# STM32C071 register map
File version: 1.3
CPU: CM0+ r0p0, little endian, MPU, no FPU, 2 interrupt priority bits
Registers are 32-bit, read-write, reset 0x0 unless marked. A register's access mark holds for its fields unless they carry their own. Offsets are from the block's base; [hi:lo] are bit positions.

## RCC — RCC address block description
Base 0x40021000
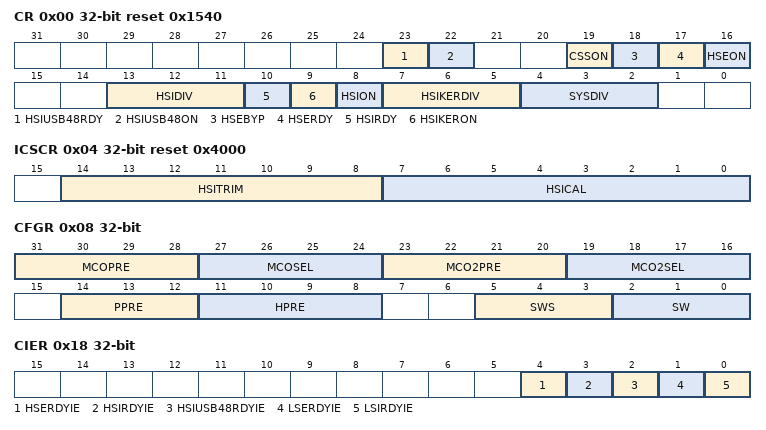
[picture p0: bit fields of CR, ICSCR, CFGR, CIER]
0x00 CR reset 0x1540 — RCC clock control register
  [23] HSIUSB48RDY — HSIUSB48 clock ready flag Set by hardware when the HSIUSB48 oscillator is enabled through HSIUSB48ON and ready to use (stable). Note: Only applicable on STM32C071xx, reserved on other devices.
  [22] HSIUSB48ON — HSIUSB48 clock enable Set and cleared by software and hardware, with hardware taking priority. Kept low by hardware as long as the device is in a low-power mode. Kept high by hardware as long as the system is clocked from HSIUSB48. Note: Only applicable on STM32C071xx, reserved on other devices.
  [19] CSSON — Clock security system enable Set by software to enable the clock security system. When the bit is set, the clock detector is enabled by hardware when the HSE oscillator is ready, and disabled by hardware if a HSE clock failure is detected. The bit is cleared by hardware upon reset.
  [18] HSEBYP — HSE crystal oscillator bypass Set and cleared by software. When the bit is set, the internal HSE oscillator is bypassed for use of an external clock. The external clock must then be enabled with the HSEON bit set. Write access to the bit is only effective when the HSE oscillator is disabled.
  [17] HSERDY ro — HSE clock ready flag Set by hardware to indicate that the HSE oscillator is stable and ready for use. Note: Upon clearing HSEON, HSERDY goes low after six HSE clock cycles.
  [16] HSEON — HSE clock enable Set and cleared by software. Cleared by hardware to stop the HSE oscillator when entering Stop, or Standby, or Shutdown mode. This bit cannot be cleared if the HSE oscillator is used directly or indirectly as the system clock.
  [13:11] HSIDIV — HSI48 clock division factor This bitfield controlled by software sets the division factor of the HSI48 clock divider to produce HSISYS clock:
  [10] HSIRDY ro — HSI48 clock ready flag Set by hardware when the HSI48 oscillator is enabled through HSION and ready to use (stable). Note: Upon clearing HSION, HSIRDY goes low after six HSI48 clock cycles.
  [9] HSIKERON — HSI48 always-enable for peripheral kernels. Set and cleared by software. Setting the bit activates the HSI48 oscillator in Run and Stop modes, regardless of the HSION bit state. The HSI48 clock can only feed USART1, USART2, and I2C1 peripherals configured with HSI48 as kernel clock. Note: Keeping the HSI48 active in Stop mode allows speeding up the serial interface communication as the HSI48 clock is ready immediately upon exiting Stop mode.
  [8] HSION — HSI48 clock enable Set and cleared by software and hardware, with hardware taking priority. Kept low by hardware as long as the device is in a low-power mode. Kept high by hardware as long as the system is clocked with a clock derived from HSI48. This includes the exit from low-power modes and the system clock fall-back to HSI48 upon failing HSE oscillator clock selected as system clock source.
  [7:5] HSIKERDIV — HSI48 kernel clock division factor This bitfield controlled by software sets the division factor of the kernel clock divider to produce HSIKER clock:
  [4:2] SYSDIV — Clock division factor for system clock Set and cleared by software. SYSCLK is result of the division by: Note: This bitfield is only available on STM32C071xx.
0x04 ICSCR reset 0x4000 (reset mask 0xFFFFFF00) — RCC internal clock source calibration register
  [14:8] HSITRIM — HSI48 clock trimming The value of this bitfield contributes to the HSICAL[7:0] bitfield value. It allows HSI48 clock frequency user trimming. The HSI48 frequency accuracy as stated in the device datasheet applies when this bitfield is left at its reset value.
  [7:0] HSICAL ro — HSI48 clock calibration This bitfield directly acts on the HSI48 clock frequency. Its value is a sum of an internal factory-programmed number and the value of the HSITRIM[6:0] bitfield. In the factory, the internal number is set to calibrate the HSI48 clock frequency to 48 MHz (with HSITRIM[6:0] left at its reset value). Refer to the device datasheet for HSI48 calibration accuracy and for the frequency trimming granularity. Note: The trimming effect presents discontinuities at HSICAL[7:0] multiples of 64.
0x08 CFGR — RCC clock configuration register
  [31:28] MCOPRE — Microcontroller clock output prescaler This bitfield is controlled by software. It sets the division factor of the clock sent to the MCO output as follows: ... Other: Reserved It is highly recommended to set this field before the MCO output is enabled. Note: Values above 0111 are only significant for STM32C071xx. On STM32C011xx and STM32C031xx devices, MCOPRE[3] is reserved.
  [27:24] MCOSEL — Microcontroller clock output clock selector This bitfield is controlled by software. It sets the clock selector for MCO output as follows: Other: reserved, must not be used Note: This clock output may have some truncated cycles at startup or during MCO clock source switching. On STM32C011xx and STM32C031xx, MCOSEL[3] is reserved.
  [23:20] MCO2PRE — Microcontroller clock output 2 prescaler This bitfield is controlled by software. It sets the division factor of the clock sent to the MCO2 output as follows: ... Other: Reserved It is highly recommended to set this field before the MCO2 output is enabled. Note: Values above 0111 are only significant for STM32C071xx. On STM32C011xx and STM32C031xx devices, MCOPRE[3] is reserved.
  [19:16] MCO2SEL — Microcontroller clock output 2 clock selector This bitfield is controlled by software. It sets the clock selector for MCO2 output as follows: Other: reserved, must not be used Note: This clock output may have some truncated cycles at startup or during MCO2 clock source switching. On STM32C011xx and STM32C031xx, MCOSEL[3] is reserved.
  [14:12] PPRE — APB prescaler This bitfield is controlled by software. To produce PCLK clock, it sets the division factor of HCLK clock as follows: 0xx: 1
  [11:8] HPRE — AHB prescaler This bitfield is controlled by software. To produce HCLK clock, it sets the division factor of SYSCLK clock as follows: 0xxx: 1
  [5:3] SWS ro — System clock switch status This bitfield is controlled by hardware to indicate the clock source used as system clock: Others: Reserved
  [2:0] SW — System clock switch This bitfield is controlled by software and hardware. The bitfield selects the clock for SYSCLK as follows: Others: Reserved The setting is forced by hardware to 000 (HSISYS selected) when the MCU exits Stop, or Standby, or Shutdown mode, or when the setting is 001 (HSE selected) and HSE oscillator failure is detected.
0x14 CRRCR ro (reset mask 0xFFFFFE00) — RCC clock recovery RC register
  [8:0] HSIUSB48CAL — HSIUSB48 clock calibration These bits are initialized at startup with the factory-programmed HSIUSB48 calibration trim value.
0x18 CIER — RCC clock interrupt enable register
  [4] HSERDYIE — HSE ready interrupt enable Set and cleared by software to enable/disable interrupt caused by the HSE oscillator stabilization:
  [3] HSIRDYIE — HSI48 ready interrupt enable Set and cleared by software to enable/disable interrupt caused by the HSI48 oscillator stabilization:
  [2] HSIUSB48RDYIE — HSIUSB48 ready interrupt enable Set and cleared by software to enable/disable interrupt caused by the HSIUSB48 oscillator stabilization: Note: Only applicable on STM32C071xx, reserved on other devices.
  [1] LSERDYIE — LSE ready interrupt enable Set and cleared by software to enable/disable interrupt caused by the LSE oscillator stabilization:
  [0] LSIRDYIE — LSI ready interrupt enable Set and cleared by software to enable/disable interrupt caused by the LSI oscillator stabilization:
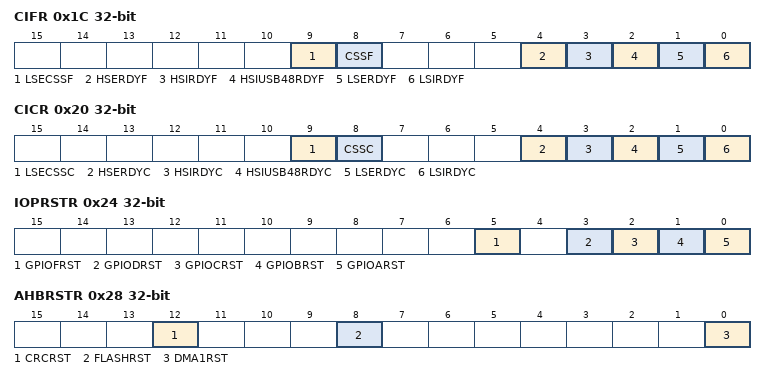
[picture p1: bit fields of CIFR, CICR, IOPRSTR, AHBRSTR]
0x1C CIFR ro — RCC clock interrupt flag register
  [9] LSECSSF — LSE clock security system interrupt flag This flag indicates a pending interrupt upon LSE clock failure. Set by hardware when a failure is detected in the LSE oscillator. Cleared by software by setting the LSECSSC bit.
  [8] CSSF — HSE clock security system interrupt flag This flag indicates a pending interrupt upon HSE clock failure. Set by hardware when a failure is detected in the HSE oscillator. Cleared by software setting the CSSC bit.
  [4] HSERDYF — HSE ready interrupt flag This flag indicates a pending interrupt upon HSE clock getting ready. Set by hardware when the HSE clock becomes stable and HSERDYIE is set. Cleared by software setting the HSERDYC bit.
  [3] HSIRDYF — HSI48 ready interrupt flag This flag indicates a pending interrupt upon HSI48 clock getting ready. Set by hardware when the HSI48 clock becomes stable and HSIRDYIE is set in response to setting the HSION (refer to RCC clock control register (RCC_CR)). When HSION is not set but the HSI48 oscillator is enabled by the peripheral through a clock request, this bit is not set and no interrupt is generated. Cleared by software setting the HSIRDYC bit.
  [2] HSIUSB48RDYF — HSIUSB48 ready interrupt flag Set by hardware when the HSIUSB48 clock becomes stable and HSIUSB48RDYIE is set as a response to setting HSIUSB48ON (refer to RCC clock control register (RCC_CR)). When HSIUSB48ON is not set but the HSIUSB48 oscillator is enabled by the peripheral through a clock request, this bit is not set and no interrupt is generated. Cleared by software setting the HSIUSB48RDYC bit. Note: Only applicable on STM32C071xx, reserved on other devices.
  [1] LSERDYF — LSE ready interrupt flag This flag indicates a pending interrupt upon LSE clock getting ready. Set by hardware when the LSE clock becomes stable and LSERDYDIE is set. Cleared by software setting the LSERDYC bit.
  [0] LSIRDYF — LSI ready interrupt flag This flag indicates a pending interrupt upon LSE clock getting ready. Set by hardware when the LSI clock becomes stable and LSIRDYDIE is set. Cleared by software setting the LSIRDYC bit.
0x20 CICR wo — RCC clock interrupt clear register
  [9] LSECSSC — LSE Clock security system interrupt clear This bit is set by software to clear the LSECSSF flag.
  [8] CSSC — Clock security system interrupt clear This bit is set by software to clear the HSECSSF flag.
  [4] HSERDYC — HSE ready interrupt clear This bit is set by software to clear the HSERDYF flag.
  [3] HSIRDYC — HSI48 ready interrupt clear This bit is set software to clear the HSIRDYF flag.
  [2] HSIUSB48RDYC — HSIUSB48 ready interrupt clear This bit is set software to clear the HSIUSB48RDYF flag. Note: Only applicable on STM32C071xx, reserved on other devices.
  [1] LSERDYC — LSE ready interrupt clear This bit is set by software to clear the LSERDYF flag.
  [0] LSIRDYC — LSI ready interrupt clear This bit is set by software to clear the LSIRDYF flag.
0x24 IOPRSTR — RCC I/O port reset register
  [5] GPIOFRST — I/O port F reset This bit is set and cleared by software.
  [3] GPIODRST — I/O port D reset This bit is set and cleared by software.
  [2] GPIOCRST — I/O port C reset This bit is set and cleared by software.
  [1] GPIOBRST — I/O port B reset This bit is set and cleared by software.
  [0] GPIOARST — I/O port A reset This bit is set and cleared by software.
0x28 AHBRSTR — RCC AHB peripheral reset register
  [12] CRCRST — CRC reset Set and cleared by software.
  [8] FLASHRST — Flash memory interface reset Set and cleared by software. This bit can only be set when the Flash memory is in power down mode.
  [0] DMA1RST — DMA1 and DMAMUX reset Set and cleared by software.
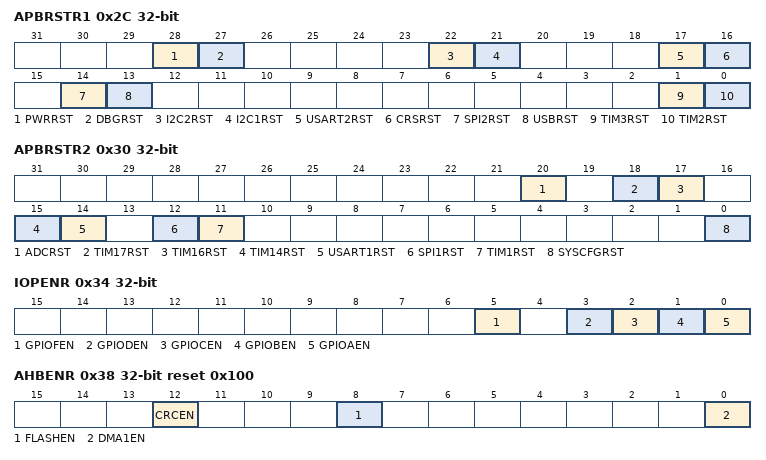
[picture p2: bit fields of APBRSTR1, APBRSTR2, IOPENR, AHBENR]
0x2C APBRSTR1 — RCC APB peripheral reset register 1
  [28] PWRRST — Power interface reset Set and cleared by software.
  [27] DBGRST — Debug support reset Set and cleared by software.
  [22] I2C2RST — I2C2 reset Set and cleared by software. Note: Only applicable on STM32C071xx, reserved on other devices.
  [21] I2C1RST — I2C1 reset Set and cleared by software.
  [17] USART2RST — USART2 reset Set and cleared by software.
  [16] CRSRST — CRS reset Set and cleared by software. Note: Only applicable on STM32C071xx, reserved on other devices.
  [14] SPI2RST — SPI2 reset Set and cleared by software. Note: Only applicable on STM32C071xx, reserved on other devices.
  [13] USBRST — USB reset Set and cleared by software. Note: Only applicable on STM32C071xx, reserved on other devices.
  [1] TIM3RST — TIM3 timer reset Set and cleared by software.
  [0] TIM2RST — TIM2 timer reset Set and cleared by software. Note: Only applicable on STM32C071xx, reserved on other devices.
0x30 APBRSTR2 — RCC APB peripheral reset register 2
  [20] ADCRST — ADC reset Set and cleared by software.
  [18] TIM17RST — TIM16 timer reset Set and cleared by software.
  [17] TIM16RST — TIM16 timer reset Set and cleared by software.
  [15] TIM14RST — TIM14 timer reset Set and cleared by software.
  [14] USART1RST — USART1 reset Set and cleared by software.
  [12] SPI1RST — SPI1 reset Set and cleared by software.
  [11] TIM1RST — TIM1 timer reset Set and cleared by software.
  [0] SYSCFGRST — SYSCFG reset Set and cleared by software.
0x34 IOPENR — RCC I/O port clock enable register
  [5] GPIOFEN — I/O port F clock enable This bit is set and cleared by software.
  [3] GPIODEN — I/O port D clock enable This bit is set and cleared by software.
  [2] GPIOCEN — I/O port C clock enable This bit is set and cleared by software.
  [1] GPIOBEN — I/O port B clock enable This bit is set and cleared by software.
  [0] GPIOAEN — I/O port A clock enable This bit is set and cleared by software.
0x38 AHBENR reset 0x100 — RCC AHB peripheral clock enable register
  [12] CRCEN — CRC clock enable Set and cleared by software.
  [8] FLASHEN — Flash memory interface clock enable Set and cleared by software. This bit can only be cleared when the Flash memory is in power down mode.
  [0] DMA1EN — DMA1 and DMAMUX clock enable Set and cleared by software. DMAMUX is enabled as long as at least one DMA peripheral is enabled.
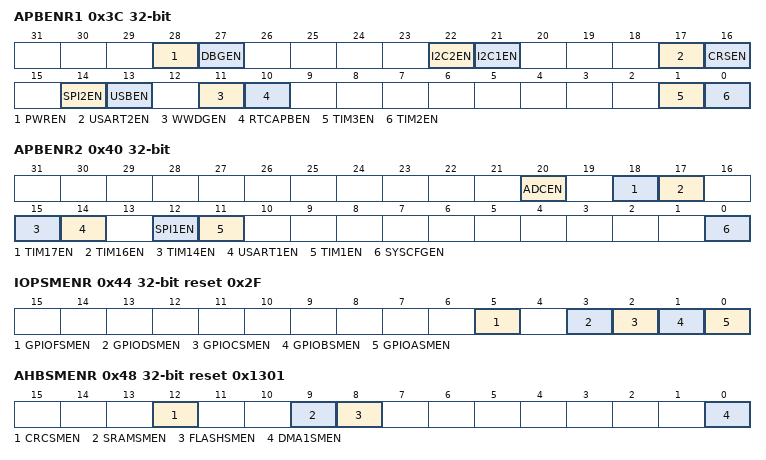
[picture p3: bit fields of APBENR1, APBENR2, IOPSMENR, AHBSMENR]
0x3C APBENR1 — RCC APB peripheral clock enable register 1
  [28] PWREN — Power interface clock enable Set and cleared by software.
  [27] DBGEN — Debug support clock enable Set and cleared by software.
  [22] I2C2EN — I2C2 clock enable Set and cleared by software.
  [21] I2C1EN — I2C1 clock enable Set and cleared by software.
  [17] USART2EN — USART2 clock enable Set and cleared by software.
  [16] CRSEN — CRS clock enable Set and cleared by software.
  [14] SPI2EN — SPI2 clock enable Set and cleared by software.
  [13] USBEN — USB clock enable Set and cleared by software.
  [11] WWDGEN — WWDG clock enable Set by software to enable the window watchdog clock. Cleared by hardware system reset This bit can also be set by hardware if the WWDG_SW option bit is 0.
  [10] RTCAPBEN — RTC APB clock enable Set and cleared by software.
  [1] TIM3EN — TIM3 timer clock enable Set and cleared by software.
  [0] TIM2EN — TIM2 timer clock enable Set and cleared by software.
0x40 APBENR2 — RCC APB peripheral clock enable register 2
  [20] ADCEN — ADC clock enable Set and cleared by software.
  [18] TIM17EN — TIM16 timer clock enable Set and cleared by software.
  [17] TIM16EN — TIM16 timer clock enable Set and cleared by software.
  [15] TIM14EN — TIM14 timer clock enable Set and cleared by software.
  [14] USART1EN — USART1 clock enable Set and cleared by software.
  [12] SPI1EN — SPI1 clock enable Set and cleared by software.
  [11] TIM1EN — TIM1 timer clock enable Set and cleared by software.
  [0] SYSCFGEN — SYSCFG clock enable Set and cleared by software.
0x44 IOPSMENR reset 0x2F — RCC I/O port in Sleep mode clock enable register
  [5] GPIOFSMEN — I/O port F clock enable during Sleep mode Set and cleared by software.
  [3] GPIODSMEN — I/O port D clock enable during Sleep mode Set and cleared by software.
  [2] GPIOCSMEN — I/O port C clock enable during Sleep mode Set and cleared by software.
  [1] GPIOBSMEN — I/O port B clock enable during Sleep mode Set and cleared by software.
  [0] GPIOASMEN — I/O port A clock enable during Sleep mode Set and cleared by software.
0x48 AHBSMENR reset 0x1301 — RCC AHB peripheral clock enable in Sleep/Stop mode register
  [12] CRCSMEN — CRC clock enable during Sleep mode Set and cleared by software.
  [9] SRAMSMEN — SRAM clock enable during Sleep mode Set and cleared by software.
  [8] FLASHSMEN — Flash memory interface clock enable during Sleep mode Set and cleared by software. This bit can be activated only when the Flash memory is in power down mode.
  [0] DMA1SMEN — DMA1 and DMAMUX clock enable during Sleep mode Set and cleared by software. Clock to DMAMUX during Sleep mode is enabled as long as the clock in Sleep mode is enabled to at least one DMA peripheral.
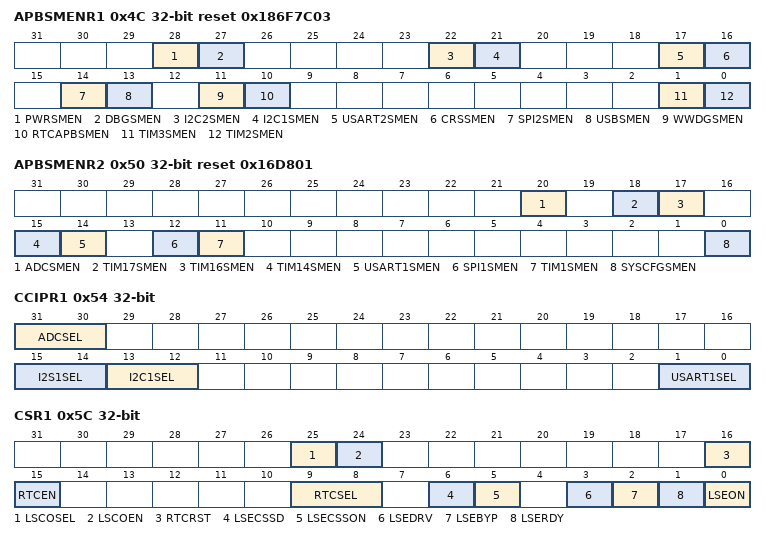
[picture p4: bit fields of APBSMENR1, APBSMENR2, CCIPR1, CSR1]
0x4C APBSMENR1 reset 0x186F7C03 — RCC APB peripheral clock enable in Sleep/Stop mode register 1
  [28] PWRSMEN — Power interface clock enable during Sleep mode Set and cleared by software.
  [27] DBGSMEN — Debug support clock enable during Sleep mode Set and cleared by software.
  [22] I2C2SMEN — I2C2 clock enable during Sleep and Stop modes Set and cleared by software. Note: Only applicable on STM32C071xx, reserved on other devices.
  [21] I2C1SMEN — I2C1 clock enable during Sleep and Stop modes Set and cleared by software.
  [17] USART2SMEN — USART2 clock enable during Sleep and Stop modes Set and cleared by software.
  [16] CRSSMEN — CRS clock enable during Sleep and Stop modes Set and cleared by software. Note: Only applicable on STM32C071xx, reserved on other devices.
  [14] SPI2SMEN — SPI2 clock enable during Sleep and Stop modes Set and cleared by software. Note: Only applicable on STM32C071xx, reserved on other devices.
  [13] USBSMEN — USB clock enable during Sleep and Stop modes Set and cleared by software. Note: Only applicable on STM32C071xx, reserved on other devices.
  [11] WWDGSMEN — WWDG clock enable during Sleep and Stop modes Set and cleared by software.
  [10] RTCAPBSMEN — RTC APB clock enable during Sleep mode Set and cleared by software.
  [1] TIM3SMEN — TIM3 timer clock enable during Sleep mode Set and cleared by software.
  [0] TIM2SMEN — TIM2 timer clock enable during Sleep mode Set and cleared by software. Note: Only applicable on STM32C071xx, reserved on other devices.
0x50 APBSMENR2 reset 0x16D801 — RCC APB peripheral clock enable in Sleep/Stop mode register 2
  [20] ADCSMEN — ADC clock enable during Sleep mode Set and cleared by software.
  [18] TIM17SMEN — TIM16 timer clock enable during Sleep mode Set and cleared by software.
  [17] TIM16SMEN — TIM16 timer clock enable during Sleep mode Set and cleared by software.
  [15] TIM14SMEN — TIM14 timer clock enable during Sleep mode Set and cleared by software.
  [14] USART1SMEN — USART1 clock enable during Sleep and Stop modes Set and cleared by software.
  [12] SPI1SMEN — SPI1 clock enable during Sleep mode Set and cleared by software.
  [11] TIM1SMEN — TIM1 timer clock enable during Sleep mode Set and cleared by software.
  [0] SYSCFGSMEN — SYSCFG clock enable during Sleep and Stop modes Set and cleared by software.
0x54 CCIPR1 — RCC peripherals independent clock configuration register 1
  [31:30] ADCSEL — ADCs clock source selection This bitfield is controlled by software to select the asynchronous clock source for ADC:
  [15:14] I2S1SEL — I2S1 clock source selection This bitfield is controlled by software to select I2S1 clock source as follows:
  [13:12] I2C1SEL — I2C1 clock source selection This bitfield is controlled by software to select I2C1 clock source as follows:
  [1:0] USART1SEL — USART1 clock source selection This bitfield is controlled by software to select USART1 clock source as follows:
0x58 CCIPR2 — RCC peripherals independent clock configuration register 2
  [12] USBSEL — USB clock source selection Set and cleared by software.
0x5C CSR1 — RCC control/status register 1
  [25] LSCOSEL — Low-speed clock output selection Set and cleared by software to select the low-speed output clock:
  [24] LSCOEN — Low-speed clock output (LSCO) enable Set and cleared by software.
  [16] RTCRST — RTC domain software reset Set and cleared by software to reset the RTC domain:
  [15] RTCEN — RTC clock enable Set and cleared by software. The bit enables clock to RTC and TAMP.
  [9:8] RTCSEL — RTC clock source selection Set by software to select the clock source for the RTC as follows: Once the RTC clock source is selected, it cannot be changed anymore unless the RTC domain is reset, or unless a failure is detected on LSE (LSECSSD is set). The RTCRST bit can be used to reset this bitfield to 00.
  [6] LSECSSD ro — CSS on LSE failure Detection Set by hardware to indicate when a failure is detected by the clock security system on the external 32 kHz oscillator (LSE):
  [5] LSECSSON — CSS on LSE enable Set by software to enable the clock security system on LSE (32 kHz) oscillator as follows: LSECSSON must be enabled after the LSE oscillator is enabled (LSEON bit enabled) and ready (LSERDY flag set by hardware), and after the RTCSEL bit is selected. Once enabled, this bit cannot be disabled, except after a LSE failure detection (LSECSSD =1). In that case the software must disable the LSECSSON bit.
  [3] LSEDRV — LSE oscillator drive capability Set by software to select the LSE oscillator drive capability as follows: Applicable when the LSE oscillator is in Xtal mode, as opposed to bypass mode.
  [2] LSEBYP — LSE oscillator bypass Set and cleared by software to bypass the LSE oscillator (in debug mode). This bit can be written only when the external 32 kHz oscillator is disabled (LSEON=0 and LSERDY=0).
  [1] LSERDY ro — LSE oscillator ready Set and cleared by hardware to indicate when the external 32 kHz oscillator is ready (stable): After the LSEON bit is cleared, LSERDY goes low after 6 external low-speed oscillator clock cycles.
  [0] LSEON — LSE oscillator enable Set and cleared by software to enable LSE oscillator:
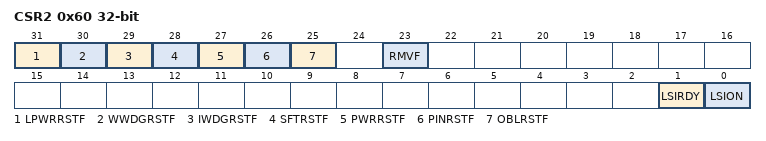
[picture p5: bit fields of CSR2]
0x60 CSR2 (reset mask 0xFFFFFF) — RCC control/status register 2
  [31] LPWRRSTF ro — Low-power reset flag Set by hardware when a reset occurs due to illegal Stop, or Standby, or Shutdown mode entry. Cleared by setting the RMVF bit. This operates only if nRST_STOP, or nRST_STDBY or nRST_SHDW option bits are cleared.
  [30] WWDGRSTF ro — Window watchdog reset flag Set by hardware when a window watchdog reset occurs. Cleared by setting the RMVF bit.
  [29] IWDGRSTF ro — Independent window watchdog reset flag Set by hardware when an independent watchdog reset domain occurs. Cleared by setting the RMVF bit.
  [28] SFTRSTF ro — Software reset flag Set by hardware when a software reset occurs. Cleared by setting the RMVF bit.
  [27] PWRRSTF ro — BOR or POR/PDR flag Set by hardware when a BOR or POR/PDR occurs. Cleared by setting the RMVF bit.
  [26] PINRSTF ro — Pin reset flag Set by hardware when a reset from the NRST pin occurs. Cleared by setting the RMVF bit.
  [25] OBLRSTF ro — Option byte loader reset flag Set by hardware when a reset from the Option byte loading occurs. Cleared by setting the RMVF bit.
  [23] RMVF — Remove reset flags Set by software to clear the reset flags.
  [1] LSIRDY ro — LSI oscillator ready Set and cleared by hardware to indicate when the LSI oscillator is ready (stable): After the LSION bit is cleared, LSIRDY goes low after 3 LSI oscillator clock cycles. This bit can be set even if LSION = 0 if the LSI is requested by the Clock Security System on LSE, by the Independent Watchdog or by the RTC.
  [0] LSION — LSI oscillator enable Set and cleared by software to enable/disable the LSI oscillator:
